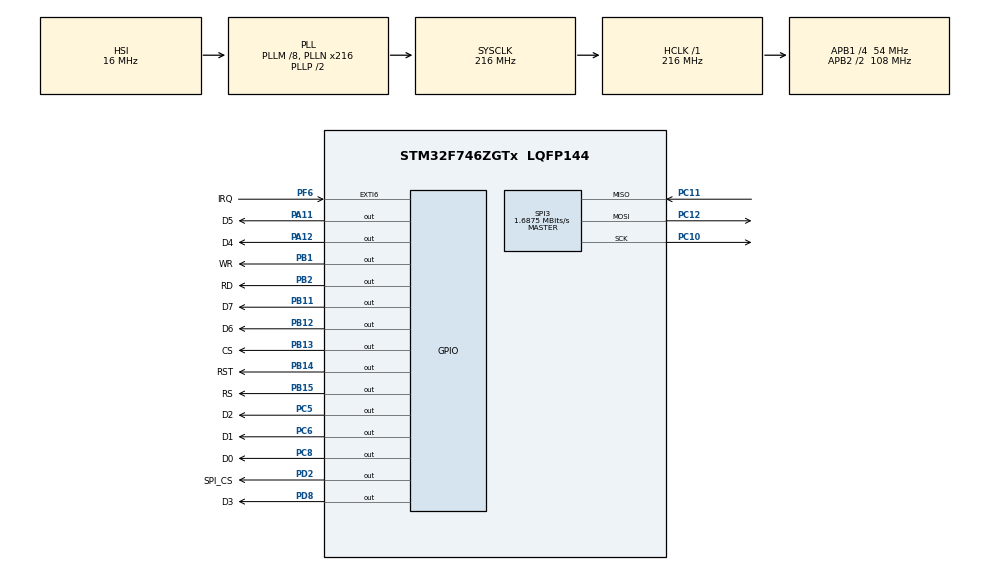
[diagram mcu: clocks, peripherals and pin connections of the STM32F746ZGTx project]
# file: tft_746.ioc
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Mcu.Family=STM32F7
Mcu.Name=STM32F746ZGTx
Mcu.Package=LQFP144
NVIC.PriorityGroup=NVIC_PRIORITYGROUP_4
PA11.GPIO_Label=D5
PA11.Signal=GPIO_Output
PA12.GPIO_Label=D4
PA12.Signal=GPIO_Output
PA13.Mode=Serial_Wire
PA13.Signal=SYS_JTMS-SWDIO
PA14.Mode=Serial_Wire
PA14.Signal=SYS_JTCK-SWCLK
PB1.GPIO_Label=WR
PB1.Signal=GPIO_Output
PB11.GPIO_Label=D7
PB11.Signal=GPIO_Output
PB12.GPIO_Label=D6
PB12.Signal=GPIO_Output
PB13.GPIO_Label=CS
PB13.Signal=GPIO_Output
PB14.GPIO_Label=RST
PB14.Signal=GPIO_Output
PB15.GPIO_Label=RS
PB15.Signal=GPIO_Output
PB2.GPIO_Label=RD
PB2.Signal=GPIO_Output
PC10.Mode=Full_Duplex_Master
PC10.Signal=SPI3_SCK
PC11.Mode=Full_Duplex_Master
PC11.Signal=SPI3_MISO
PC12.Mode=Full_Duplex_Master
PC12.Signal=SPI3_MOSI
PC5.GPIO_Label=D2
PC5.Signal=GPIO_Output
PC6.GPIO_Label=D1
PC6.Signal=GPIO_Output
PC8.GPIO_Label=D0
PC8.Signal=GPIO_Output
PD2.GPIO_Label=SPI_CS
PD2.Signal=GPIO_Output
PD8.GPIO_Label=D3
PD8.Signal=GPIO_Output
PF6.GPIO_Label=IRQ
PF6.Signal=GPXTI6
PH0/OSC_IN.Mode=HSE-External-Oscillator
PH0/OSC_IN.Signal=RCC_OSC_IN
PH1/OSC_OUT.Mode=HSE-External-Oscillator
PH1/OSC_OUT.Signal=RCC_OSC_OUT
ProjectManager.HeapSize=0x200
ProjectManager.StackSize=0x400
ProjectManager.TargetToolchain=MDK-ARM V5.27
RCC.AHBFreq_Value=216000000
RCC.APB1CLKDivider=RCC_HCLK_DIV4
RCC.APB1Freq_Value=54000000
RCC.APB1TimFreq_Value=108000000
RCC.APB2CLKDivider=RCC_HCLK_DIV2
RCC.APB2Freq_Value=108000000
RCC.APB2TimFreq_Value=216000000
RCC.CortexFreq_Value=216000000
RCC.HCLKFreq_Value=216000000
RCC.HSE_VALUE=25000000
RCC.HSI_VALUE=16000000
RCC.LSE_VALUE=32768
RCC.PLLM=8
RCC.PLLN=216
RCC.SYSCLKFreq_VALUE=216000000
RCC.SYSCLKSource=RCC_SYSCLKSOURCE_PLLCLK
RCC.USBFreq_Value=216000000
RCC.VCOOutputFreq_Value=432000000
SPI3.BaudRatePrescaler=SPI_BAUDRATEPRESCALER_32
SPI3.CalculateBaudRate=1.6875 MBits/s
SPI3.DataSize=SPI_DATASIZE_8BIT
SPI3.Direction=SPI_DIRECTION_2LINES
SPI3.Mode=SPI_MODE_MASTER
SPI3.VirtualType=VM_MASTER
board=custom

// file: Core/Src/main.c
/* USER CODE BEGIN Header */
/**
  ******************************************************************************
  * @file           : main.c
  * @brief          : Main program body
  ******************************************************************************
  * @attention
  *
  * <h2><center>&copy; Copyright (c) 2021 STMicroelectronics.
  * All rights reserved.</center></h2>
  *
  * This software component is licensed by ST under BSD 3-Clause license,
  * the "License"; You may not use this file except in compliance with the
  * License. You may obtain a copy of the License at:
  *                        opensource.org/licenses/BSD-3-Clause
  *
  ******************************************************************************
  */
/* USER CODE END Header */
#include "main.h"

/* USER CODE BEGIN Includes */
#include "STM_MY_TFT_ILI9341.h"
#include "stdbool.h"
#include "XPT2046_touch.h"

//#include <XPT2046_touch.h>

/* USER CODE END Includes */

SPI_HandleTypeDef hspi3;

/* USER CODE BEGIN PV */
//touch_t t
uint16_t x,y;
/* USER CODE END PV */

void SystemClock_Config(void);
static void MX_GPIO_Init(void);
static void MX_SPI3_Init(void);

int main(void)
{

  /* MCU Configuration--------------------------------------------------------*/

  /* Reset of all peripherals, Initializes the Flash interface and the Systick. */
  HAL_Init();

  /* Configure the system clock */
  SystemClock_Config();

  /* Initialize all configured peripherals */
  MX_GPIO_Init();
  MX_SPI3_Init();
  /* USER CODE BEGIN 2 */
  ILI9341_Init();
  ILI9341_setRotation(3);
  ILI9341_fillScreen(GREEN);

  /* USER CODE END 2 */

  /* Infinite loop */
  /* USER CODE BEGIN WHILE */
  while (1)
  {

	XPT2046_TouchGetCoordinates(&x,&y);

	  if(XPT2046_TouchPressed())
	  {
		ILI9341_drawCircle(x,y,10,BLACK);
	  }
    /* USER CODE END WHILE */

  }
}

void SystemClock_Config(void)
{
  RCC_OscInitTypeDef RCC_OscInitStruct = {0};
  RCC_ClkInitTypeDef RCC_ClkInitStruct = {0};

  /** Configure the main internal regulator output voltage
  */
  __HAL_RCC_PWR_CLK_ENABLE();
  __HAL_PWR_VOLTAGESCALING_CONFIG(PWR_REGULATOR_VOLTAGE_SCALE1);
  /** Initializes the RCC Oscillators according to the specified parameters
  * in the RCC_OscInitTypeDef structure.
  */
  RCC_OscInitStruct.OscillatorType = RCC_OSCILLATORTYPE_HSI;
  RCC_OscInitStruct.HSIState = RCC_HSI_ON;
  RCC_OscInitStruct.HSICalibrationValue = RCC_HSICALIBRATION_DEFAULT;
  RCC_OscInitStruct.PLL.PLLState = RCC_PLL_ON;
  RCC_OscInitStruct.PLL.PLLSource = RCC_PLLSOURCE_HSI;
  RCC_OscInitStruct.PLL.PLLM = 8;
  RCC_OscInitStruct.PLL.PLLN = 216;
  RCC_OscInitStruct.PLL.PLLP = RCC_PLLP_DIV2;
  RCC_OscInitStruct.PLL.PLLQ = 2;
  if (HAL_RCC_OscConfig(&RCC_OscInitStruct) != HAL_OK)
  {
    Error_Handler();
  }
  /** Activate the Over-Drive mode
  */
  if (HAL_PWREx_EnableOverDrive() != HAL_OK)
  {
    Error_Handler();
  }
  /** Initializes the CPU, AHB and APB buses clocks
  */
  RCC_ClkInitStruct.ClockType = RCC_CLOCKTYPE_HCLK|RCC_CLOCKTYPE_SYSCLK
                              |RCC_CLOCKTYPE_PCLK1|RCC_CLOCKTYPE_PCLK2;
  RCC_ClkInitStruct.SYSCLKSource = RCC_SYSCLKSOURCE_PLLCLK;
  RCC_ClkInitStruct.AHBCLKDivider = RCC_SYSCLK_DIV1;
  RCC_ClkInitStruct.APB1CLKDivider = RCC_HCLK_DIV4;
  RCC_ClkInitStruct.APB2CLKDivider = RCC_HCLK_DIV2;

  if (HAL_RCC_ClockConfig(&RCC_ClkInitStruct, FLASH_LATENCY_7) != HAL_OK)
  {
    Error_Handler();
  }
}

static void MX_SPI3_Init(void)
{

  /* SPI3 parameter configuration*/
  hspi3.Instance = SPI3;
  hspi3.Init.Mode = SPI_MODE_MASTER;
  hspi3.Init.Direction = SPI_DIRECTION_2LINES;
  hspi3.Init.DataSize = SPI_DATASIZE_8BIT;
  hspi3.Init.CLKPolarity = SPI_POLARITY_LOW;
  hspi3.Init.CLKPhase = SPI_PHASE_1EDGE;
  hspi3.Init.NSS = SPI_NSS_SOFT;
  hspi3.Init.BaudRatePrescaler = SPI_BAUDRATEPRESCALER_64;
  hspi3.Init.FirstBit = SPI_FIRSTBIT_MSB;
  hspi3.Init.TIMode = SPI_TIMODE_DISABLE;
  hspi3.Init.CRCCalculation = SPI_CRCCALCULATION_DISABLE;
  hspi3.Init.CRCPolynomial = 10;
  hspi3.Init.CRCLength = SPI_CRC_LENGTH_DATASIZE;
  hspi3.Init.NSSPMode = SPI_NSS_PULSE_DISABLE;
  if (HAL_SPI_Init(&hspi3) != HAL_OK)
  {
    Error_Handler();
  }

}

static void MX_GPIO_Init(void)
{
  GPIO_InitTypeDef GPIO_InitStruct = {0};

  /* GPIO Ports Clock Enable */
  __HAL_RCC_GPIOF_CLK_ENABLE();
  __HAL_RCC_GPIOH_CLK_ENABLE();
  __HAL_RCC_GPIOC_CLK_ENABLE();
  __HAL_RCC_GPIOB_CLK_ENABLE();
  __HAL_RCC_GPIOD_CLK_ENABLE();
  __HAL_RCC_GPIOA_CLK_ENABLE();

  /*Configure GPIO pin Output Level */
  HAL_GPIO_WritePin(GPIOC, D2_Pin|D1_Pin|D0_Pin, GPIO_PIN_RESET);

  /*Configure GPIO pin Output Level */
  HAL_GPIO_WritePin(GPIOB, WR_Pin|RD_Pin|D7_Pin|D6_Pin
                          |CS_Pin|RST_Pin|RS_Pin, GPIO_PIN_RESET);

  /*Configure GPIO pin Output Level */
  HAL_GPIO_WritePin(GPIOD, D3_Pin|SPI_CS_Pin, GPIO_PIN_RESET);

  /*Configure GPIO pin Output Level */
  HAL_GPIO_WritePin(GPIOA, D5_Pin|D4_Pin, GPIO_PIN_RESET);

  /*Configure GPIO pin : IRQ_Pin */
  GPIO_InitStruct.Pin = IRQ_Pin;
  GPIO_InitStruct.Mode = GPIO_MODE_IT_RISING;
  GPIO_InitStruct.Pull = GPIO_NOPULL;
  HAL_GPIO_Init(IRQ_GPIO_Port, &GPIO_InitStruct);

  /*Configure GPIO pins : D2_Pin D1_Pin D0_Pin */
  GPIO_InitStruct.Pin = D2_Pin|D1_Pin|D0_Pin;
  GPIO_InitStruct.Mode = GPIO_MODE_OUTPUT_PP;
  GPIO_InitStruct.Pull = GPIO_NOPULL;
  GPIO_InitStruct.Speed = GPIO_SPEED_FREQ_LOW;
  HAL_GPIO_Init(GPIOC, &GPIO_InitStruct);

  /*Configure GPIO pins : WR_Pin RD_Pin D7_Pin D6_Pin
                           CS_Pin RST_Pin RS_Pin */
  GPIO_InitStruct.Pin = WR_Pin|RD_Pin|D7_Pin|D6_Pin
                          |CS_Pin|RST_Pin|RS_Pin;
  GPIO_InitStruct.Mode = GPIO_MODE_OUTPUT_PP;
  GPIO_InitStruct.Pull = GPIO_NOPULL;
  GPIO_InitStruct.Speed = GPIO_SPEED_FREQ_LOW;
  HAL_GPIO_Init(GPIOB, &GPIO_InitStruct);

  /*Configure GPIO pins : D3_Pin SPI_CS_Pin */
  GPIO_InitStruct.Pin = D3_Pin|SPI_CS_Pin;
  GPIO_InitStruct.Mode = GPIO_MODE_OUTPUT_PP;
  GPIO_InitStruct.Pull = GPIO_NOPULL;
  GPIO_InitStruct.Speed = GPIO_SPEED_FREQ_LOW;
  HAL_GPIO_Init(GPIOD, &GPIO_InitStruct);

  /*Configure GPIO pins : D5_Pin D4_Pin */
  GPIO_InitStruct.Pin = D5_Pin|D4_Pin;
  GPIO_InitStruct.Mode = GPIO_MODE_OUTPUT_PP;
  GPIO_InitStruct.Pull = GPIO_NOPULL;
  GPIO_InitStruct.Speed = GPIO_SPEED_FREQ_LOW;
  HAL_GPIO_Init(GPIOA, &GPIO_InitStruct);

}

void Error_Handler(void)
{
}

/************************ (C) COPYRIGHT STMicroelectronics *****END OF FILE****/
